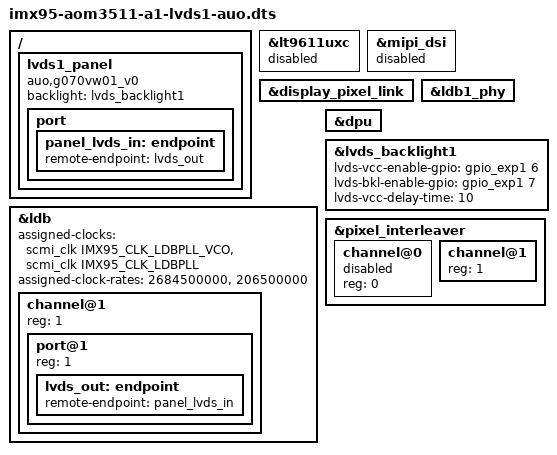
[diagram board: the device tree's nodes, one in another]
// SPDX-License-Identifier: (GPL-2.0+ OR MIT)
/*
 * Copyright 2024 NXP
 */

#include "imx95-aom3511-a1.dts"

/ {
	lvds1_panel {
		compatible = "auo,g070vw01_v0";
		backlight = <&lvds_backlight1>;

		port {
			panel_lvds_in: endpoint {
				remote-endpoint = <&lvds_out>;
			};
		};
	};
};

&lt9611uxc {
	status = "disabled";
};

&mipi_dsi {
	status = "disabled";
};

&display_pixel_link {
	status = "okay";
};

&ldb {
	#address-cells = <1>;
	#size-cells = <0>;
	assigned-clocks = <&scmi_clk IMX95_CLK_LDBPLL_VCO>,
			  <&scmi_clk IMX95_CLK_LDBPLL>;
	assigned-clock-rates = <2684500000>, <206500000>;
	status = "okay";

	channel@1 {
		#address-cells = <1>;
		#size-cells = <0>;
		status = "okay";
		reg = <1>;

		port@1 {
			reg = <1>;

			lvds_out: endpoint {
				remote-endpoint = <&panel_lvds_in>;
			};
		};
	};
};

&ldb1_phy {
	status = "okay";
};

&dpu {
        /delete-property/ assigned-clocks;
        /delete-property/ assigned-clock-parents;
        /delete-property/ assigned-clock-rates;
};

&lvds_backlight1 {
	lvds-vcc-enable-gpio = <&gpio_exp1 6 GPIO_ACTIVE_HIGH>;	/* LCD1_VDD_EN */
	lvds-bkl-enable-gpio = <&gpio_exp1 7 GPIO_ACTIVE_HIGH>;	/* LCD1_BKLT_EN */
	lvds-vcc-delay-time = <10>;
	status = "okay";
};

&pixel_interleaver {
	#address-cells = <1>;
	#size-cells = <0>;
	status = "okay";

	channel@0 {
		reg = <0>;
		status = "disabled";
	};

	channel@1 {
		reg = <1>;
		status = "okay";
	};
};

